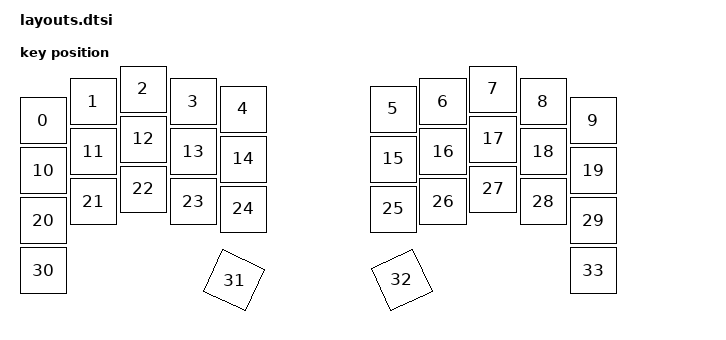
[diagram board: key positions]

#include <physical_layouts.dtsi>
/ {
    physical_layout0: physical_layout0 {
        compatible = "zmk,physical-layout";
        display-name = "Layout";
        keys
            = <&key_physical_attrs 100 100 50 63 0 0 0>
			,<&key_physical_attrs 100 100 150 25 0 0 0>
			,<&key_physical_attrs 100 100 250 0 0 0 0>
			,<&key_physical_attrs 100 100 350 25 0 0 0>
			,<&key_physical_attrs 100 100 450 40 0 0 0>
			,<&key_physical_attrs 100 100 750 40 0 0 0>
			,<&key_physical_attrs 100 100 850 25 0 0 0>
			,<&key_physical_attrs 100 100 950 0 0 0 0>
			,<&key_physical_attrs 100 100 1050 25 0 0 0>
			,<&key_physical_attrs 100 100 1150 63 0 0 0>
			,<&key_physical_attrs 100 100 50 163 0 0 0>
			,<&key_physical_attrs 100 100 150 125 0 0 0>
			,<&key_physical_attrs 100 100 250 100 0 0 0>
			,<&key_physical_attrs 100 100 350 125 0 0 0>
			,<&key_physical_attrs 100 100 450 140 0 0 0>
			,<&key_physical_attrs 100 100 750 140 0 0 0>
			,<&key_physical_attrs 100 100 850 125 0 0 0>
			,<&key_physical_attrs 100 100 950 100 0 0 0>
			,<&key_physical_attrs 100 100 1050 125 0 0 0>
			,<&key_physical_attrs 100 100 1150 163 0 0 0>
			,<&key_physical_attrs 100 100 50 263 0 0 0>
			,<&key_physical_attrs 100 100 150 225 0 0 0>
			,<&key_physical_attrs 100 100 250 200 0 0 0>
			,<&key_physical_attrs 100 100 350 225 0 0 0>
			,<&key_physical_attrs 100 100 450 240 0 0 0>
			,<&key_physical_attrs 100 100 750 240 0 0 0>
			,<&key_physical_attrs 100 100 850 225 0 0 0>
			,<&key_physical_attrs 100 100 950 200 0 0 0>
			,<&key_physical_attrs 100 100 1050 225 0 0 0>
			,<&key_physical_attrs 100 100 1150 263 0 0 0>
			,<&key_physical_attrs 100 100 50 363 0 0 0>
			,<&key_physical_attrs 100 100 458 366 2500 458 366>
			,<&key_physical_attrs 100 100 751 408 (-2500) 751 408>
			,<&key_physical_attrs 100 100 1150 363 0 0 0>
            ;
    };
};
    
